# STM32N655xx register map
File version: 1.0
Registers are 32-bit, read-write, reset 0x0 unless marked. A register's access mark holds for its fields unless they carry their own. Offsets are from the block's base; [hi:lo] are bit positions; {n}, {i} and the like mark numbered series; 'fields as' and 'values as' point back to an identical list.

## PSSI
Base 0x48026400
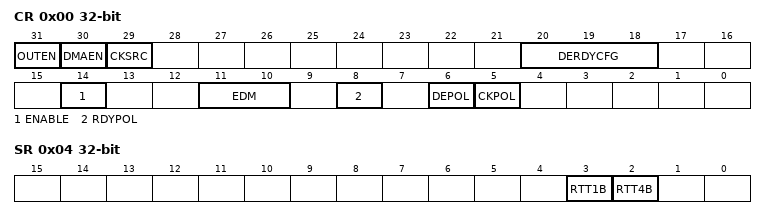
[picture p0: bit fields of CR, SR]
0x00 CR — PSSI control register
  [31] OUTEN — Data direction selection
  [30] DMAEN — DMA enable
  [29] CKSRC — Clock source
  [20:18] DERDYCFG — Data enable and ready configuration
  [14] ENABLE — PSSI enable
  [11:10] EDM — Extended data mode
  [8] RDYPOL — Ready polarity
  [6] DEPOL — Data enable polarity
  [5] CKPOL — Parallel data clock polarity
0x04 SR — PSSI status register
  [3] RTT1B — Ready to transfer one byte
  [2] RTT4B — Ready to transfer four bytes
0x08 RIS — PSSI raw interrupt status register
  [1] OVR_RIS — Data buffer overrun/underrun raw interrupt status
0x0C IER — PSSI interrupt enable register
  [1] OVR_IE — Data buffer overrun/underrun interrupt enable
0x10 MIS — PSSI masked interrupt status register
  [1] OVR_MIS — Data buffer overrun/underrun masked interrupt status
0x14 ICR — PSSI interrupt clear register
  [1] OVR_ISC — Data buffer overrun/underrun interrupt status clear
0x28 DR — PSSI data register
  [31:0] DR — Data register

## DLYB_SDMMC2
Base 0x48026C00
Same registers: DLYB_SDMMC1 0x48028000
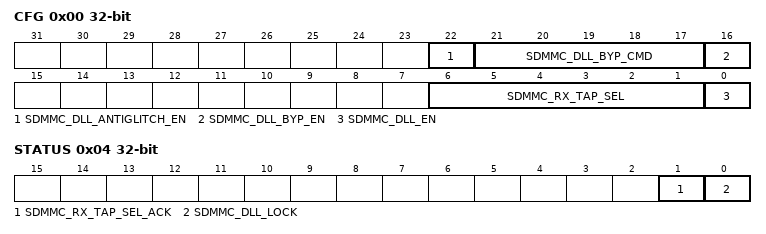
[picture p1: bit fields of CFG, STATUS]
0x00 CFG — Delay Block Configuration Register
  [22] SDMMC_DLL_ANTIGLITCH_EN — Enable Antiglitch
  [21:17] SDMMC_DLL_BYP_CMD — Select Taps values
  [16] SDMMC_DLL_BYP_EN — DLYB Bypass mode enable
  [6:1] SDMMC_RX_TAP_SEL — Select the phase for RX DLYB
  [0] SDMMC_DLL_EN — Delay Block enable
0x04 STATUS — Delay Block Status Register
  [1] SDMMC_RX_TAP_SEL_ACK — RX delay selection acknowledge
  [0] SDMMC_DLL_LOCK — DLYB lock mode enable

## DCMI
Base 0x48028400
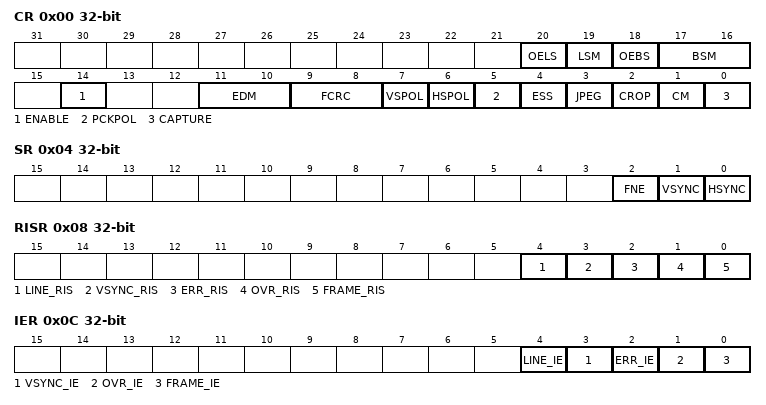
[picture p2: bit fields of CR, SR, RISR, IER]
0x00 CR — DCMI control register 1
  [20] OELS
  [19] LSM
  [18] OEBS
  [17:16] BSM
  [14] ENABLE
  [11:10] EDM — DCMI Extended data mode EDM[1:0]
  [9:8] FCRC — DCMI Frame capture rate control FCRC[1:0]
  [7] VSPOL
  [6] HSPOL
  [5] PCKPOL
  [4] ESS
  [3] JPEG
  [2] CROP
  [1] CM
  [0] CAPTURE
0x04 SR — DCMI status register
  [2] FNE, [1] VSYNC, [0] HSYNC
0x08 RISR — DCMI raw interrupt status register
  [4] LINE_RIS, [3] VSYNC_RIS, [2] ERR_RIS, [1] OVR_RIS, [0] FRAME_RIS
0x0C IER — DCMI interrupt enable register
  [4] LINE_IE, [3] VSYNC_IE, [2] ERR_IE, [1] OVR_IE, [0] FRAME_IE
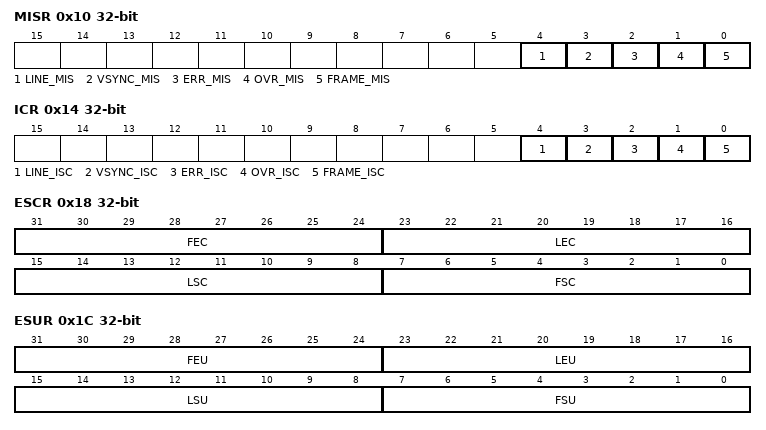
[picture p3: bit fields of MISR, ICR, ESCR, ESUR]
0x10 MISR — DCMI masked interrupt status register
  [4] LINE_MIS, [3] VSYNC_MIS, [2] ERR_MIS, [1] OVR_MIS, [0] FRAME_MIS
0x14 ICR — DCMI interrupt clear register
  [4] LINE_ISC, [3] VSYNC_ISC, [2] ERR_ISC, [1] OVR_ISC, [0] FRAME_ISC
0x18 ESCR — DCMI embedded synchronization code register
  [31:24] FEC, [23:16] LEC, [15:8] LSC, [7:0] FSC
0x1C ESUR — DCMI embedded synchronization unmask register
  [31:24] FEU, [23:16] LEU, [15:8] LSU, [7:0] FSU
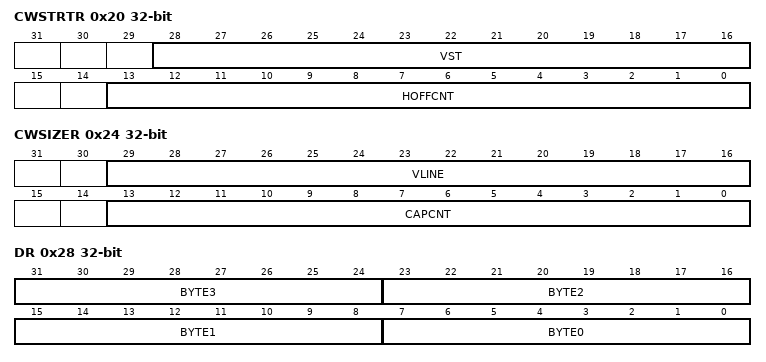
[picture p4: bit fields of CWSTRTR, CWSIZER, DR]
0x20 CWSTRTR — DCMI crop window start
  [28:16] VST, [13:0] HOFFCNT
0x24 CWSIZER — DCMI crop window size
  [29:16] VLINE, [13:0] CAPCNT
0x28 DR — DCMI data register
  [8n+7:8n] BYTE{n} (n=0..3)

## XSPIM — XSPI IO Manager
Base 0x4802B400
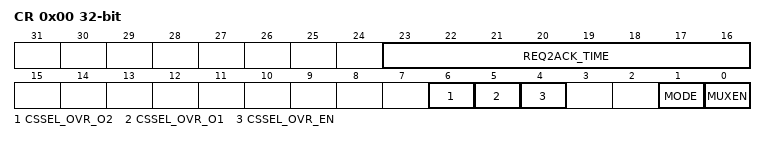
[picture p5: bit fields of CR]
0x00 CR — XSPI IO Manager Control Register
  [23:16] REQ2ACK_TIME — REQ to ACK Time
  [6] CSSEL_OVR_O2 — Chip Select Selector Override Setting For XSPI2
  [5] CSSEL_OVR_O1 — Chip Select Selector Override Setting For XSPI1
  [4] CSSEL_OVR_EN — Chip Select Selector Override Enable
  [1] MODE — Multiplexing Mode
  [0] MUXEN — Multiplexed Mode Enable

## MCE1
Base 0x4802B800
Same registers: MCE2 0x4802BC00, MCE3 0x4802C000, MCE4 0x4802E000
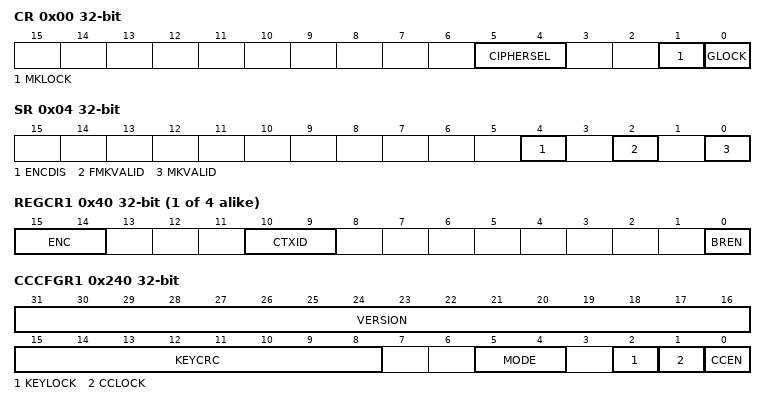
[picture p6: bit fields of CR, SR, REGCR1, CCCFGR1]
0x00 CR — MCE configuration register
  [5:4] CIPHERSEL — MCE Cipher selection
  [1] MKLOCK — MCE master and fast master keys lock
  [0] GLOCK — MCE global lock
0x04 SR — MCE status register
  [4] ENCDIS — MCE encryption disabled flag
  [2] FMKVALID — MCE fast master key valid flag
  [0] MKVALID — MCE master key valid flag
0x08 IASR — MCE illegal access status register
  [1] IAEF — MCE illegal access error flag
0x0C IACR — MCE illegal access clear register
  [1] IAEF — MCE illegal access error clear bit
0x10 IAIER — MCE illegal access interrupt enable register
  [1] IAEIE — MCE illegal access error interrupt enable
0x24 IADDR — MCE illegal address register
  [31:0] IADD — MCE illegal access
{0x30+0x10*i} REGCR{i} (i=1..4) — MCE region configuration register
  [15:14] ENC — MCE encrypted region
  [10:9] CTXID — MCE context ID
  [0] BREN — MCE base region enable
{0x34+0x10*i} SADDR{i} (i=1..4) — MCE region start address register
  [31:12] BADDSTART — MCE region address start
{0x38+0x10*i} EADDR{i} (i=1..4) — MCE region end address register
  [31:12] BADDEND — MCE region address end
{0x200+4i} MKEYR{i} (i=0..7) — MCE master key register {i}
  [31:0] MKEY — MCE master key, bits [{32i+31}:{32i}]
{0x220+4i} FMKEYR{i} (i=0..7) — MCE fast master key register {i}
  [31:0] FMKEY — MCE fast master key, bits [{32i+31}:{32i}]
0x240 CCCFGR1 — MCE cipher context configuration register
  [31:16] VERSION — MCE cipher context version
  [15:8] KEYCRC — MCE cipher context key CRC
  [5:4] MODE — MCE authorized cipher mode
  [2] KEYLOCK — MCE cipher context key lock
  [1] CCLOCK — MCE cipher context lock
  [0] CCEN — MCE cipher context enable
0x244 CCNR01 — MCE cipher context nonce register 0
  [31:0] SCNONCE — MCE cipher context stream cipher nonce, bits [31:0]
0x248 CCNR1 — MCE cipher context nonce register 1
  [31:0] SCNONCE — MCE cipher context stream cipher nonce, bits [63:32]
0x24C CCKEYR01 — MCE cipher context key register 0
  [31:0] KEY — MCE cipher context key, bits [31:0]
0x250 CCKEYR1 — MCE cipher context key register 1
  [31:0] KEY — MCE fast master key, bits [63:32]
0x254 CCKEYR21 — MCE cipher context key register 2
  [31:0] KEY — MCE fast master key, bits [95:64]
0x258 CCKEYR31 — MCE cipher context key register 3
  [31:0] KEY — MCE fast master key, bits [127:96]
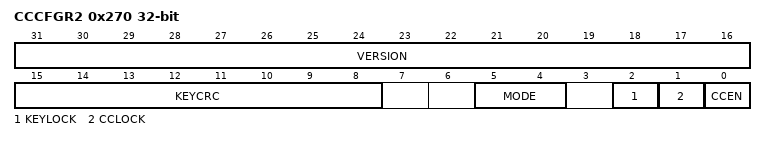
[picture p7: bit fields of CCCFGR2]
0x270 CCCFGR2 — MCE cipher context configuration register
  fields as CCCFGR1
0x274 CCNR02 — MCE cipher context nonce register 0
  [31:0] SCNONCE — MCE cipher context stream cipher nonce, bits [31:0]
0x278 CCNR12 — MCE cipher context nonce register 1
  fields as CCNR1
0x27C CCKEYR02 — MCE cipher context key register 0
  [31:0] KEY — MCE cipher context key, bits [31:0]
0x280 CCKEYR12 — MCE cipher context key register 1
  [31:0] KEY — MCE fast master key, bits [63:32]
0x284 CCKEYR2 — MCE cipher context key register 2
  [31:0] KEY — MCE fast master key, bits [95:64]
0x288 CCKEYR32 — MCE cipher context key register 3
  [31:0] KEY — MCE fast master key, bits [127:96]

## GFXMMU
Base 0x48030000
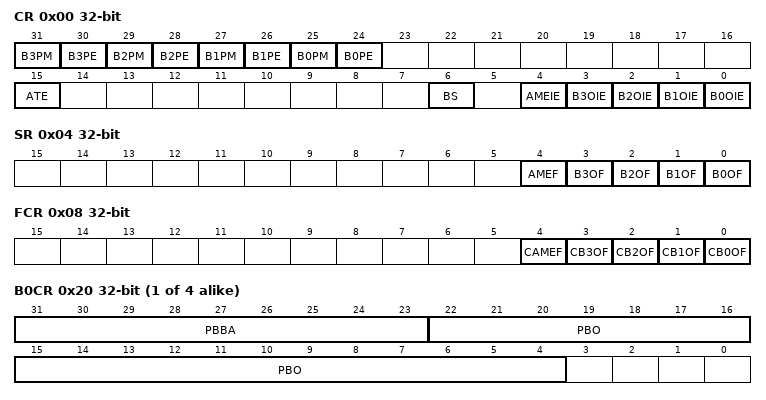
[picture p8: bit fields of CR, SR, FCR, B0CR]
0x00 CR — GFXMMU configuration register
  [31] B3PM — Buffer 0 packing mode
  [30] B3PE — Buffer 0 packing enable
  [29] B2PM — Buffer 0 packing mode
  [28] B2PE — Buffer 0 packing enable
  [27] B1PM — Buffer 1 packing mode
  [26] B1PE — Buffer 1 packing enable
  [25] B0PM — Buffer 0 packing mode
  [24] B0PE — Buffer 0 packing enable
  [15] ATE — Address translation enable
  [6] BS — Block size
  [4] AMEIE — AHB master error interrupt enable
  [n] B{n}OIE (n=0..3) — Buffer {n} overflow interrupt enable
0x04 SR — GFXMMU status register
  [4] AMEF — AXI master error flag
  [n] B{n}OF (n=0..3) — Buffer {n} overflow flag
0x08 FCR — GFXMMU flag clear register
  [4] CAMEF — Clear AHB master error flag
  [n] CB{n}OF (n=0..3) — Clear buffer {n} overflow flag
0x10 DVR — GFXMMU default value register
  [31:0] DV — DV[31:0] bits (Default value)
0x14 DAR — GFXMMU default alpha register
{0x20+4i} B{i}CR (i=0..3) — GFXMMU buffer {i} configuration register
  [31:23] PBBA — PBBA[31:23] bits (Physical buffer base address)
  [22:4] PBO — PB0[22:4] bits (Physical buffer offset)
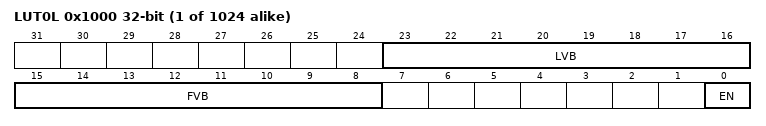
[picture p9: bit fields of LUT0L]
{0x1000+8i} LUT{i}L (i=0..1023) — GFXMMU LUT registers
  [23:16] LVB — LVB[7:0] bits (Last visible block)
  [15:8] FVB — FVB[7:0] bits (First visible block)
  [0] EN — Enable
{0x1004+8i} LUT{i}H (i=0..1023) — GFXMMU LUT registers
  [17:0] LO — LO[17:0] bits (Line offset)

## ICACHE — Instruction Cache
Base 0x48035000
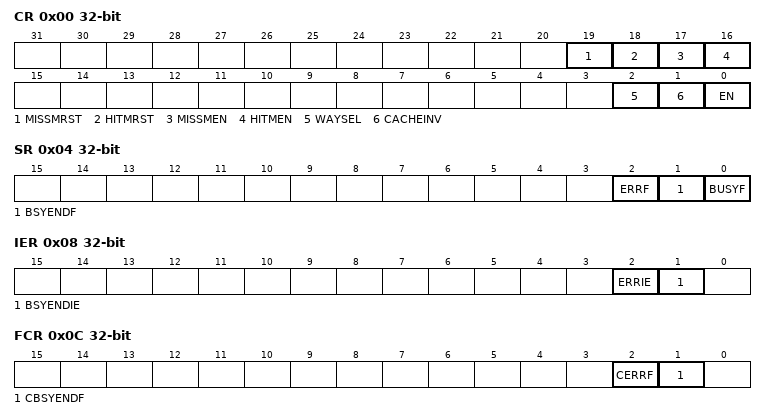
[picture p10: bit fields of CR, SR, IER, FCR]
0x00 CR — ICACHE control register
  [19] MISSMRST — Miss monitor reset
  [18] HITMRST — Hit monitor reset
  [17] MISSMEN — Miss monitor enable
  [16] HITMEN — Hit monitor enable
  [2] WAYSEL — Ways selection
    0=ICACHE_1WAY (1-way cache (direct mapped cache)); 1=ICACHE_4WAYS (4-ways set associative cache (default))
  [1] CACHEINV — Cache invalidation
  [0] EN — Enable
0x04 SR — ICACHE status register
  [2] ERRF — Cache error flag
  [1] BSYENDF — Busy end flag
  [0] BUSYF — Busy flag
0x08 IER — ICACHE interrupt enable register
  [2] ERRIE — Cache error interrupt enable
  [1] BSYENDIE — Busy end interrupt enable
0x0C FCR — ICACHE flag clear register
  [2] CERRF — Cache error flag clear
  [1] CBSYENDF — Busy end flag clear
0x10 HMONR — ICACHE hit monitor register
  [31:0] HITMON — Cache hit monitor register
0x14 MMONR — ICACHE miss monitor register
  [15:0] MISSMON — Cache miss monitor register

## USB1_HS_PHYC
Base 0x4803FC00
Same registers: USB2_HS_PHYC 0x480C0000
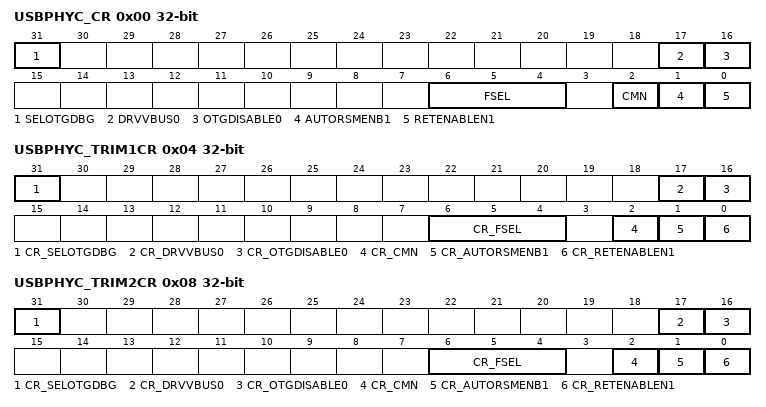
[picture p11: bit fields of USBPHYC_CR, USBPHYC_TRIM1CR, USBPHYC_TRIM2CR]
0x00 USBPHYC_CR — USB HS PHY Control Register
  [31] SELOTGDBG — Select HS PHY debug port
  [17] DRVVBUS0 — Drive VBUS 0
  [16] OTGDISABLE0
  [6:4] FSEL — Frequency selection
  [2] CMN — Controls the power down of analog blocks during Suspend and Sleep
  [1] AUTORSMENB1 — Auto-resume mode enable
  [0] RETENABLEN1 — Retention mode enable
0x04 USBPHYC_TRIM1CR — USB HS PHY Trimming_1 Register
  [31] CR_SELOTGDBG — Select HS PHY debug port
  [17] CR_DRVVBUS0 — Drive VBUS 0
  [16] CR_OTGDISABLE0 — OTG disable 0
  [6:4] CR_FSEL — Frequency selection
  [2] CR_CMN — Controls the power down of analog blocks during Suspend and Sleep
  [1] CR_AUTORSMENB1 — Auto-resume mode enable
  [0] CR_RETENABLEN1 — Retention mode enable
0x08 USBPHYC_TRIM2CR — USB HS PHY Trimming_2 Register
  fields as USBPHYC_TRIM1CR
